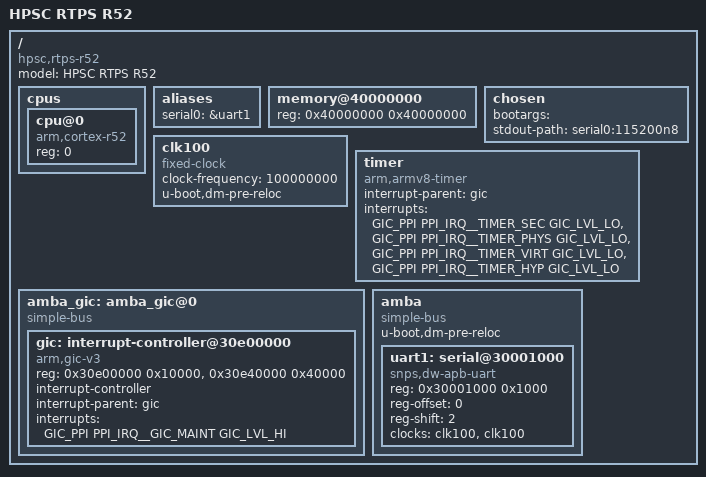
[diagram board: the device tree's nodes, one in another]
// SPDX-License-Identifier: GPL-2.0
/*
 * dts file for Xilinx ZynqMP R5
 *
 * (C) Copyright 2018, Xilinx, Inc.
 *
 * Michal Simek <michal.simek@xilinx.com>
 */

/dts-v1/;

/* Copies from Qemu Device Tree repo */
#include "hpsc-irqs.dtsh"
#include "hpsc-busids.dtsh"

#define GIC_SPI 0
#define GIC_PPI 1
#define GIC_EDGE_RISE 1
#define GIC_EDGE_FALL 2
#define GIC_EDGE_BOTH 3
#define GIC_LVL_HI 4
#define GIC_LVL_LO 8

/ {
	#address-cells = <1>;
	#size-cells = <1>;
	compatible = "hpsc,rtps-r52";
	model = "HPSC RTPS R52";

	cpus {
		#address-cells = <0x1>;
		#size-cells = <0x0>;

		cpu@0 {
			compatible = "arm,cortex-r52";
			device_type = "cpu";
			reg = <0>;
		};
	};

	aliases {
		serial0 = &uart1;
	};

	memory@40000000 {
		device_type = "memory";
		reg = <0x40000000 0x40000000>;
	};

	chosen {
		bootargs = "";
		stdout-path = "serial0:115200n8";
	};

	clk100: clk100 {
		compatible = "fixed-clock";
		#clock-cells = <0>;
		clock-frequency = <100000000>;
		u-boot,dm-pre-reloc;
	};

	timer {
		compatible = "arm,armv8-timer";
		interrupt-parent = <&gic>;
		interrupts = <GIC_PPI PPI_IRQ__TIMER_SEC  GIC_LVL_LO>,
			     <GIC_PPI PPI_IRQ__TIMER_PHYS GIC_LVL_LO>,
			     <GIC_PPI PPI_IRQ__TIMER_VIRT GIC_LVL_LO>,
			     <GIC_PPI PPI_IRQ__TIMER_HYP  GIC_LVL_LO>;
	};

	amba_gic: amba_gic@0 {
		#address-cells = <1>;
		#size-cells = <1>;
		compatible = "simple-bus";
		ranges = <0 0 0xffffffff>;
		gic: interrupt-controller@30e00000 {
			compatible = "arm,gic-v3";
			#interrupt-cells = <3>;
			reg = <0x30e00000 0x10000>,
			      <0x30e40000 0x40000>;
			interrupt-controller;
			interrupt-parent = <&gic>;
			interrupts = <GIC_PPI PPI_IRQ__GIC_MAINT GIC_LVL_HI>;
		};
	};

	amba {
		u-boot,dm-pre-reloc;
		compatible = "simple-bus";
		#address-cells = <1>;
		#size-cells = <1>;
		ranges;

		uart1: serial@30001000 {
			compatible = "snps,dw-apb-uart";
			status = "okay";
			reg = <0x30001000 0x1000>;
			reg-offset = <0>;
			reg-shift = <2>; /* register width: 4-byte = 32-bit */
			clocks = <&clk100 &clk100>;
			clock-names = "uart_clk", "pclk";
		};
	};
};
